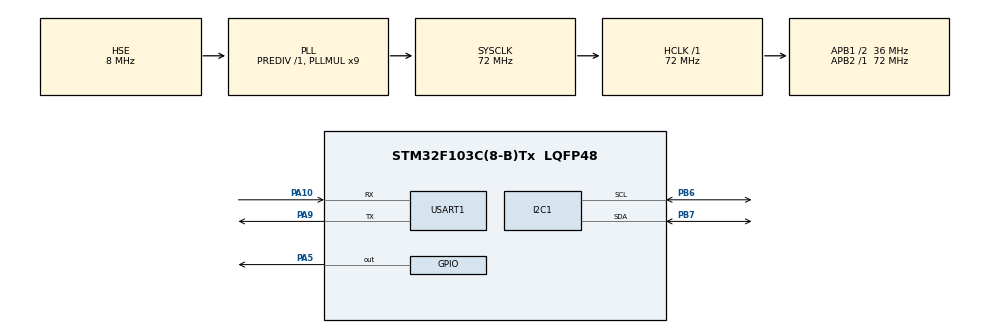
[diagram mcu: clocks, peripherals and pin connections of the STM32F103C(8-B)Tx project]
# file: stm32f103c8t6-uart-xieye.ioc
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Mcu.Family=STM32F1
Mcu.Name=STM32F103C(8-B)Tx
Mcu.Package=LQFP48
NVIC.PriorityGroup=NVIC_PRIORITYGROUP_4
NVIC.USART1_IRQn=true\:0\:0\:false\:false\:true\:true\:true\:true
PA10.Mode=Asynchronous
PA10.Signal=USART1_RX
PA13.Mode=Serial_Wire
PA13.Signal=SYS_JTMS-SWDIO
PA14.Mode=Serial_Wire
PA14.Signal=SYS_JTCK-SWCLK
PA5.PinState=GPIO_PIN_SET
PA5.Signal=GPIO_Output
PA9.Mode=Asynchronous
PA9.Signal=USART1_TX
PB6.Mode=I2C
PB6.Signal=I2C1_SCL
PB7.Mode=I2C
PB7.Signal=I2C1_SDA
PD0-OSC_IN.Mode=HSE-External-Oscillator
PD0-OSC_IN.Signal=RCC_OSC_IN
PD1-OSC_OUT.Mode=HSE-External-Oscillator
PD1-OSC_OUT.Signal=RCC_OSC_OUT
ProjectManager.HeapSize=0x200
ProjectManager.StackSize=0x400
ProjectManager.TargetToolchain=MDK-ARM V5.32
RCC.AHBFreq_Value=72000000
RCC.APB1CLKDivider=RCC_HCLK_DIV2
RCC.APB1Freq_Value=36000000
RCC.APB1TimFreq_Value=72000000
RCC.APB2Freq_Value=72000000
RCC.APB2TimFreq_Value=72000000
RCC.HCLKFreq_Value=72000000
RCC.PLLMUL=RCC_PLL_MUL9
RCC.PLLSourceVirtual=RCC_PLLSOURCE_HSE
RCC.SYSCLKFreq_VALUE=72000000
RCC.SYSCLKSource=RCC_SYSCLKSOURCE_PLLCLK
RCC.USBFreq_Value=72000000
TIM1.Prescaler=72-1
USART1.VirtualMode=VM_ASYNC
VP_TIM1_VS_ClockSourceINT.Mode=Internal
board=custom

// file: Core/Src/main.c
/* USER CODE BEGIN Header */
/**
  ******************************************************************************
  * @file           : main.c
  * @brief          : Main program body
  ******************************************************************************
  * @attention
  *
  * Copyright (c) 2026 STMicroelectronics.
  * All rights reserved.
  *
  * This software is licensed under terms that can be found in the LICENSE file
  * in the root directory of this software component.
  * If no LICENSE file comes with this software, it is provided AS-IS.
  *
  ******************************************************************************
  */
/* USER CODE END Header */
#include "main.h"
#include "i2c.h"
#include "tim.h"
#include "usart.h"
#include "gpio.h"

/* USER CODE BEGIN Includes */
#include "oled.h"
#include "bsp_dht11.h"
#include "command.h"
#include <stdio.h>
#include "err.h"
/* USER CODE END Includes */

/* USER CODE BEGIN PD */
uint8_t readBuffer[10];
DHT11_Data_TypeDef DHT11_Data;
/* USER CODE END PD */

void SystemClock_Config(void);

/* USER CODE BEGIN 0 */
void HAL_UARTEx_RxEventCallback(UART_HandleTypeDef *huart, uint16_t Size){
	if(huart == &huart1){
		Command_Write(readBuffer,Size);
		HAL_UARTEx_ReceiveToIdle_IT(&huart1,readBuffer,sizeof(readBuffer));
	}
}
/* USER CODE END 0 */

int main(void)
{

  /* MCU Configuration--------------------------------------------------------*/

  /* Reset of all peripherals, Initializes the Flash interface and the Systick. */
  HAL_Init();

  /* Configure the system clock */
  SystemClock_Config();

  /* Initialize all configured peripherals */
	HAL_Delay(2000);//稳定上电
  MX_GPIO_Init();
  MX_I2C1_Init();
  MX_TIM1_Init();
  MX_USART1_UART_Init();
	OLED_Init();
	OLED_Clear();
  /* USER CODE BEGIN 2 */
	HAL_UARTEx_ReceiveToIdle_IT(&huart1,readBuffer,sizeof(readBuffer));
  /* USER CODE END 2 */

  /* Infinite loop */
  while (1)
  {
		uint8_t command[50];
		uint8_t commandLength = 0;
		CommandStatus_t status;
		status = Command_GetCommand(command, &commandLength);

		switch (status)
		{
		case CMD_NONE:
				break;

		case CMD_OK:
				if (commandLength == 0)
				{
						Send_Error(ERR_INVALID_LENGTH);
						Log_Print("[ERR] Empty command\r\n");
						break;
				}

				switch (command[0])
				{
				case 0x01:
						Log_Print("[CMD] Read DHT11\r\n");

						HAL_Delay(2000);

						if (DHT11_ReadData(&DHT11_Data))
						{
								char message[50];
								uint16_t len = (uint16_t)snprintf(message, sizeof(message),
										"Humidity:%d.%d%% Temperature:%d.%dC\r\n",
										DHT11_Data.humi_int, DHT11_Data.humi_deci,
										DHT11_Data.temp_int, DHT11_Data.temp_deci);

								HAL_UART_Transmit(&huart1, (uint8_t *)message, len, 1000);

								OLED_Clear();
								OLED_ShowZh16x16ByIndex(0, 2, 0);
								OLED_ShowZh16x16ByIndex(16, 2, 1);
								OLED_ShowZh16x16ByIndex(32, 2, 2);
								OLED_ShowNum8x16(48, 2, (int16_t)(DHT11_Data.humi_int * 10 + DHT11_Data.humi_deci), 1);

								OLED_ShowZh16x16ByIndex(0, 6, 3);
								OLED_ShowZh16x16ByIndex(16, 6, 4);
								OLED_ShowZh16x16ByIndex(32, 6, 5);
								OLED_ShowNum8x16(48, 6, (int16_t)(DHT11_Data.temp_int * 10 + DHT11_Data.temp_deci), 1);
						}
						else
						{
								Send_Error(ERR_SENSOR_FAIL);
								Log_Print("[ERR] DHT11 read failed\r\n");
						}
						break;

				case 0x02:
						Log_Print("[CMD] OLED clear\r\n");
						OLED_Clear();
						break;

				case 0x03:
				{
						Log_Print("[CMD] Return last DHT11 data\r\n");

						char message[50];
						uint16_t len = (uint16_t)snprintf(message, sizeof(message),
								"Humidity:%d.%d%% Temperature:%d.%dC\r\n",
								DHT11_Data.humi_int, DHT11_Data.humi_deci,
								DHT11_Data.temp_int, DHT11_Data.temp_deci);

						HAL_UART_Transmit(&huart1, (uint8_t *)message, len, 1000);
						break;
				}

				default:
						Send_Error(ERR_UNKNOWN_CMD);
						Log_Print("[ERR] Unknown command\r\n");
						break;
				}
				break;

		case CMD_ERR_CHECKSUM:
				Send_Error(ERR_CHECKSUM);
				Log_Print("[ERR] Checksum error\r\n");
				break;

		case CMD_ERR_LENGTH:
				Send_Error(ERR_INVALID_LENGTH);
				Log_Print("[ERR] Length error\r\n");
				break;

		case CMD_ERR_TIMEOUT:
				Send_Error(ERR_TIMEOUT);
				Log_Print("[ERR] Frame timeout\r\n");
				break;

		case CMD_ERR_HEAD:
				// Parser already dropped one byte; avoid log spam for line noise.
				break;

		default:
				Send_Error(0xFF);
				Log_Print("[ERR] Unknown parser status\r\n");
				break;
		}
  }
}

void SystemClock_Config(void)
{
  RCC_OscInitTypeDef RCC_OscInitStruct = {0};
  RCC_ClkInitTypeDef RCC_ClkInitStruct = {0};

  /** Initializes the RCC Oscillators according to the specified parameters
  * in the RCC_OscInitTypeDef structure.
  */
  RCC_OscInitStruct.OscillatorType = RCC_OSCILLATORTYPE_HSE;
  RCC_OscInitStruct.HSEState = RCC_HSE_ON;
  RCC_OscInitStruct.HSEPredivValue = RCC_HSE_PREDIV_DIV1;
  RCC_OscInitStruct.HSIState = RCC_HSI_ON;
  RCC_OscInitStruct.PLL.PLLState = RCC_PLL_ON;
  RCC_OscInitStruct.PLL.PLLSource = RCC_PLLSOURCE_HSE;
  RCC_OscInitStruct.PLL.PLLMUL = RCC_PLL_MUL9;
  if (HAL_RCC_OscConfig(&RCC_OscInitStruct) != HAL_OK)
  {
    Error_Handler();
  }

  /** Initializes the CPU, AHB and APB buses clocks
  */
  RCC_ClkInitStruct.ClockType = RCC_CLOCKTYPE_HCLK|RCC_CLOCKTYPE_SYSCLK
                              |RCC_CLOCKTYPE_PCLK1|RCC_CLOCKTYPE_PCLK2;
  RCC_ClkInitStruct.SYSCLKSource = RCC_SYSCLKSOURCE_PLLCLK;
  RCC_ClkInitStruct.AHBCLKDivider = RCC_SYSCLK_DIV1;
  RCC_ClkInitStruct.APB1CLKDivider = RCC_HCLK_DIV2;
  RCC_ClkInitStruct.APB2CLKDivider = RCC_HCLK_DIV1;

  if (HAL_RCC_ClockConfig(&RCC_ClkInitStruct, FLASH_LATENCY_2) != HAL_OK)
  {
    Error_Handler();
  }
}

void Error_Handler(void)
{
  __disable_irq();
  while (1)
  {
  }
}
